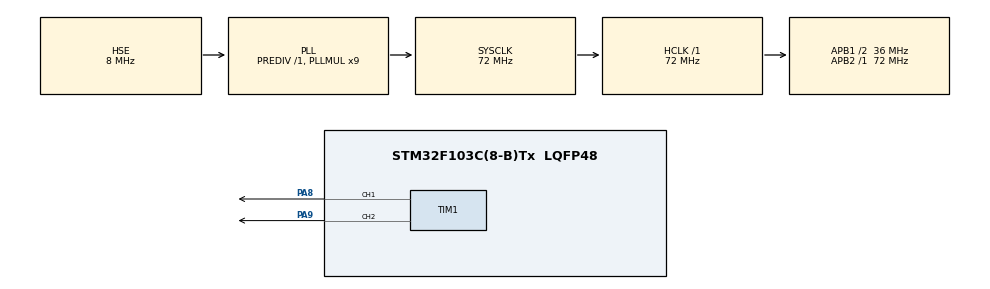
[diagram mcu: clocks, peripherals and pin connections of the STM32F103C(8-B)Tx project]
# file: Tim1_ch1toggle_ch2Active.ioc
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Mcu.Family=STM32F1
Mcu.Name=STM32F103C(8-B)Tx
Mcu.Package=LQFP48
NVIC.PriorityGroup=NVIC_PRIORITYGROUP_4
NVIC.TIM1_CC_IRQn=true\:0\:0\:false\:false\:true
PA13.Mode=Serial_Wire
PA13.Signal=SYS_JTMS-SWDIO
PA14.Mode=Serial_Wire
PA14.Signal=SYS_JTCK-SWCLK
PA8.GPIO_ModeDefaultPP=GPIO_MODE_AF_PP
PA8.GPIO_Speed=GPIO_SPEED_FREQ_HIGH
PA8.Signal=S_TIM1_CH1
PA9.GPIO_Speed=GPIO_SPEED_FREQ_HIGH
PA9.Signal=S_TIM1_CH2
PD0-OSC_IN.Mode=HSE-External-Oscillator
PD0-OSC_IN.Signal=RCC_OSC_IN
PD1-OSC_OUT.Mode=HSE-External-Oscillator
PD1-OSC_OUT.Signal=RCC_OSC_OUT
ProjectManager.HeapSize=0x200
ProjectManager.StackSize=0x400
ProjectManager.TargetToolchain=SW4STM32
RCC.AHBFreq_Value=72000000
RCC.APB1CLKDivider=RCC_HCLK_DIV2
RCC.APB1Freq_Value=36000000
RCC.APB1TimFreq_Value=72000000
RCC.APB2Freq_Value=72000000
RCC.APB2TimFreq_Value=72000000
RCC.HCLKFreq_Value=72000000
RCC.PLLMUL=RCC_PLL_MUL9
RCC.PLLSourceVirtual=RCC_PLLSOURCE_HSE
RCC.SYSCLKFreq_VALUE=72000000
RCC.SYSCLKSource=RCC_SYSCLKSOURCE_PLLCLK
RCC.USBFreq_Value=72000000
SH.S_TIM1_CH1.0=TIM1_CH1,Output Compare1 CH1
SH.S_TIM1_CH2.0=TIM1_CH2,Output Compare2 CH2
TIM1.Channel-Output\ Compare1\ CH1=TIM_CHANNEL_1
TIM1.Channel-Output\ Compare2\ CH2=TIM_CHANNEL_2
TIM1.OCMode_1=TIM_OCMODE_TOGGLE
TIM1.OCMode_2=TIM_OCMODE_TOGGLE
TIM1.TIM_MasterOutputTrigger=TIM_TRGO_OC1
VP_TIM1_VS_ClockSourceINT.Mode=Internal
board=Tim1_ch1toggle_ch2Active

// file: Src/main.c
/**
  ******************************************************************************
  * File Name          : main.c
  * Description        : Main program body
  ******************************************************************************
  ** This notice applies to any and all portions of this file
  * that are not between comment pairs USER CODE BEGIN and
  * USER CODE END. Other portions of this file, whether
  * inserted by the user or by software development tools
  * are owned by their respective copyright owners.
  *
  * COPYRIGHT(c) 2017 STMicroelectronics
  *
  * Redistribution and use in source and binary forms, with or without modification,
  * are permitted provided that the following conditions are met:
  *   1. Redistributions of source code must retain the above copyright notice,
  *      this list of conditions and the following disclaimer.
  *   2. Redistributions in binary form must reproduce the above copyright notice,
  *      this list of conditions and the following disclaimer in the documentation
  *      and/or other materials provided with the distribution.
  *   3. Neither the name of STMicroelectronics nor the names of its contributors
  *      may be used to endorse or promote products derived from this software
  *      without specific prior written permission.
  *
  * THIS SOFTWARE IS PROVIDED BY THE COPYRIGHT HOLDERS AND CONTRIBUTORS "AS IS"
  * AND ANY EXPRESS OR IMPLIED WARRANTIES, INCLUDING, BUT NOT LIMITED TO, THE
  * IMPLIED WARRANTIES OF MERCHANTABILITY AND FITNESS FOR A PARTICULAR PURPOSE ARE
  * DISCLAIMED. IN NO EVENT SHALL THE COPYRIGHT HOLDER OR CONTRIBUTORS BE LIABLE
  * FOR ANY DIRECT, INDIRECT, INCIDENTAL, SPECIAL, EXEMPLARY, OR CONSEQUENTIAL
  * DAMAGES (INCLUDING, BUT NOT LIMITED TO, PROCUREMENT OF SUBSTITUTE GOODS OR
  * SERVICES; LOSS OF USE, DATA, OR PROFITS; OR BUSINESS INTERRUPTION) HOWEVER
  * CAUSED AND ON ANY THEORY OF LIABILITY, WHETHER IN CONTRACT, STRICT LIABILITY,
  * OR TORT (INCLUDING NEGLIGENCE OR OTHERWISE) ARISING IN ANY WAY OUT OF THE USE
  * OF THIS SOFTWARE, EVEN IF ADVISED OF THE POSSIBILITY OF SUCH DAMAGE.
  *
  ******************************************************************************
  */
#include "main.h"
#include "stm32f1xx_hal.h"

TIM_HandleTypeDef htim1;

/* USER CODE BEGIN PV */
/* Private variables ---------------------------------------------------------*/

__IO uint32_t uhCCR1_Val = 16384;
__IO uint32_t uhCCR2_Val = 20480;
__IO uint32_t uhCCR3_Val = 10240;
__IO uint32_t uhCCR4_Val = 5120;
uint32_t uhCapture = 0;

/* Timer handler declaration */
TIM_HandleTypeDef TimHandle;

/* Timer Output Compare Configuration Structure declaration */
TIM_OC_InitTypeDef sConfig;

/* Counter Prescaler value */
uint32_t uwPrescalerValue = 0;

/* USER CODE END PV */

void SystemClock_Config(void);
static void MX_GPIO_Init(void);
static void MX_TIM1_Init(void);
void HAL_TIM_MspPostInit(TIM_HandleTypeDef *htim);

/* USER CODE BEGIN PFP */
/* Private function prototypes -----------------------------------------------*/
void configureTimerFrequencyOC(TIM_TypeDef* timx, uint32_t frequency,
		uint32_t channelx, uint8_t dutyCycle);
void HAL_TIM_OC_DelayElapsedCallback(TIM_HandleTypeDef *htim)
{
  /* TIM3_CH1 toggling with frequency = 256.35 Hz */
  if(htim->Channel == HAL_TIM_ACTIVE_CHANNEL_1)
  {
    uhCapture = HAL_TIM_ReadCapturedValue(htim, TIM_CHANNEL_1);
    /* Set the Capture Compare Register value */
    __HAL_TIM_SetCompare(&TimHandle, TIM_CHANNEL_1, (uhCapture + uhCCR1_Val));
  }

  /* TIM3_CH2 toggling with frequency = 256.35 Hz */
  if(htim->Channel == HAL_TIM_ACTIVE_CHANNEL_2)
  {
    uhCapture = HAL_TIM_ReadCapturedValue(htim, TIM_CHANNEL_2);
    /* Set the Capture Compare Register value */
    __HAL_TIM_SetCompare(&TimHandle, TIM_CHANNEL_2, (uhCapture + uhCCR2_Val));
  }

  /* TIM3_CH3 toggling with frequency = 256.35 Hz */
  if(htim->Channel == HAL_TIM_ACTIVE_CHANNEL_3)
  {
    uhCapture = HAL_TIM_ReadCapturedValue(htim, TIM_CHANNEL_3);
    /* Set the Capture Compare Register value */
    __HAL_TIM_SetCompare(&TimHandle, TIM_CHANNEL_3, (uhCapture + uhCCR3_Val));
  }

  /* TIM3_CH4 toggling with frequency = 256.35 Hz */
  if(htim->Channel == HAL_TIM_ACTIVE_CHANNEL_4)
  {
    uhCapture = HAL_TIM_ReadCapturedValue(htim, TIM_CHANNEL_4);
    /* Set the Capture Compare Register value */
    __HAL_TIM_SetCompare(&TimHandle, TIM_CHANNEL_4, (uhCapture + uhCCR4_Val));
  }
}
/* USER CODE END PFP */

/* USER CODE BEGIN 0 */
uint32_t uhTimerPeriod = 0;
/* USER CODE END 0 */

int main(void)
{

  /* MCU Configuration----------------------------------------------------------*/

  /* Reset of all peripherals, Initializes the Flash interface and the Systick. */
  HAL_Init();

  /* Configure the system clock */
  SystemClock_Config();

  /* Initialize all configured peripherals */
  MX_GPIO_Init();
  MX_TIM1_Init();

  /* USER CODE BEGIN 2 */
  uwPrescalerValue = (uint32_t)(((SystemCoreClock /2) / 21000000) - 1);
	TimHandle.Instance = TIM1;

	TimHandle.Init.Period = 65535;
	TimHandle.Init.Prescaler = 1;
	TimHandle.Init.ClockDivision = 0;
	TimHandle.Init.CounterMode = TIM_COUNTERMODE_UP;
	if (HAL_TIM_OC_Init(&TimHandle) != HAL_OK) {
		/* Initialization Error */
		Error_Handler();
	}

	//===============================================================

	sConfig.OCMode = TIM_OCMODE_TOGGLE;
	  sConfig.Pulse = uhCCR1_Val;
	  sConfig.OCPolarity = TIM_OCPOLARITY_LOW;
	  if(HAL_TIM_OC_ConfigChannel(&TimHandle, &sConfig, TIM_CHANNEL_1) != HAL_OK)
	  {
	    /* Configuration Error */
	    Error_Handler();
	  }

	  /* Output Compare Toggle Mode configuration: Channel2 */
	  sConfig.Pulse = uhCCR2_Val;
	  if(HAL_TIM_OC_ConfigChannel(&TimHandle, &sConfig, TIM_CHANNEL_2) != HAL_OK)
	  {
	    /* Configuration Error */
	    Error_Handler();
	  }

	  /* Output Compare Toggle Mode configuration: Channel3 */
	  sConfig.Pulse = uhCCR3_Val;
	  if(HAL_TIM_OC_ConfigChannel(&TimHandle, &sConfig, TIM_CHANNEL_3) != HAL_OK)
	  {
	    /* Configuration Error */
	    Error_Handler();
	  }

	  /* Output Compare Toggle Mode configuration: Channel4 */
	  sConfig.Pulse = uhCCR4_Val;
	  if(HAL_TIM_OC_ConfigChannel(&TimHandle, &sConfig, TIM_CHANNEL_4) != HAL_OK)
	  {
	    /* Configuration Error */
	    Error_Handler();
	  }

	    /*##-3- Start signals generation #######################################*/
	  /* Start channel 1 in Output compare mode */
	  if(HAL_TIM_OC_Start_IT(&TimHandle, TIM_CHANNEL_1) != HAL_OK)
	  {
	    /* Starting Error */
	    Error_Handler();
	  }
	  /* Start channel 2 in Output compare mode */
	  if(HAL_TIM_OC_Start_IT(&TimHandle, TIM_CHANNEL_2) != HAL_OK)
	  {
	    /* Starting Error */
	    Error_Handler();
	  }
	  /* Start channel 3 in Output compare mode */
	  if(HAL_TIM_OC_Start_IT(&TimHandle, TIM_CHANNEL_3) != HAL_OK)
	  {
	    /* Starting Error */
	    Error_Handler();
	  }
	  /* Start channel 4 in Output compare mode */
	  if(HAL_TIM_OC_Start_IT(&TimHandle, TIM_CHANNEL_4) != HAL_OK)
	  {
	    /* Starting Error */
	    Error_Handler();
	  }

  /* USER CODE END 2 */

  /* Infinite loop */
	while (1) {

	}

}

/** System Clock Configuration
*/
void SystemClock_Config(void)
{

  RCC_OscInitTypeDef RCC_OscInitStruct;
  RCC_ClkInitTypeDef RCC_ClkInitStruct;

    /**Initializes the CPU, AHB and APB busses clocks
    */
  RCC_OscInitStruct.OscillatorType = RCC_OSCILLATORTYPE_HSE;
  RCC_OscInitStruct.HSEState = RCC_HSE_ON;
  RCC_OscInitStruct.HSEPredivValue = RCC_HSE_PREDIV_DIV1;
  RCC_OscInitStruct.HSIState = RCC_HSI_ON;
  RCC_OscInitStruct.PLL.PLLState = RCC_PLL_ON;
  RCC_OscInitStruct.PLL.PLLSource = RCC_PLLSOURCE_HSE;
  RCC_OscInitStruct.PLL.PLLMUL = RCC_PLL_MUL9;
  if (HAL_RCC_OscConfig(&RCC_OscInitStruct) != HAL_OK)
  {
    _Error_Handler(__FILE__, __LINE__);
  }

    /**Initializes the CPU, AHB and APB busses clocks
    */
  RCC_ClkInitStruct.ClockType = RCC_CLOCKTYPE_HCLK|RCC_CLOCKTYPE_SYSCLK
                              |RCC_CLOCKTYPE_PCLK1|RCC_CLOCKTYPE_PCLK2;
  RCC_ClkInitStruct.SYSCLKSource = RCC_SYSCLKSOURCE_PLLCLK;
  RCC_ClkInitStruct.AHBCLKDivider = RCC_SYSCLK_DIV1;
  RCC_ClkInitStruct.APB1CLKDivider = RCC_HCLK_DIV2;
  RCC_ClkInitStruct.APB2CLKDivider = RCC_HCLK_DIV1;

  if (HAL_RCC_ClockConfig(&RCC_ClkInitStruct, FLASH_LATENCY_2) != HAL_OK)
  {
    _Error_Handler(__FILE__, __LINE__);
  }

    /**Configure the Systick interrupt time
    */
  HAL_SYSTICK_Config(HAL_RCC_GetHCLKFreq()/1000);

    /**Configure the Systick
    */
  HAL_SYSTICK_CLKSourceConfig(SYSTICK_CLKSOURCE_HCLK);

  /* SysTick_IRQn interrupt configuration */
  HAL_NVIC_SetPriority(SysTick_IRQn, 0, 0);
}

/* TIM1 init function */
static void MX_TIM1_Init(void)
{

  TIM_ClockConfigTypeDef sClockSourceConfig;
  TIM_MasterConfigTypeDef sMasterConfig;
  TIM_OC_InitTypeDef sConfigOC;
  TIM_BreakDeadTimeConfigTypeDef sBreakDeadTimeConfig;

  htim1.Instance = TIM1;
  htim1.Init.Prescaler = 0;
  htim1.Init.CounterMode = TIM_COUNTERMODE_UP;
  htim1.Init.Period = 0;
  htim1.Init.ClockDivision = TIM_CLOCKDIVISION_DIV1;
  htim1.Init.RepetitionCounter = 0;
  if (HAL_TIM_Base_Init(&htim1) != HAL_OK)
  {
    _Error_Handler(__FILE__, __LINE__);
  }

  sClockSourceConfig.ClockSource = TIM_CLOCKSOURCE_INTERNAL;
  if (HAL_TIM_ConfigClockSource(&htim1, &sClockSourceConfig) != HAL_OK)
  {
    _Error_Handler(__FILE__, __LINE__);
  }

  if (HAL_TIM_OC_Init(&htim1) != HAL_OK)
  {
    _Error_Handler(__FILE__, __LINE__);
  }

  sMasterConfig.MasterOutputTrigger = TIM_TRGO_OC1;
  sMasterConfig.MasterSlaveMode = TIM_MASTERSLAVEMODE_DISABLE;
  if (HAL_TIMEx_MasterConfigSynchronization(&htim1, &sMasterConfig) != HAL_OK)
  {
    _Error_Handler(__FILE__, __LINE__);
  }

  sConfigOC.OCMode = TIM_OCMODE_TOGGLE;
  sConfigOC.Pulse = 0;
  sConfigOC.OCPolarity = TIM_OCPOLARITY_HIGH;
  sConfigOC.OCNPolarity = TIM_OCNPOLARITY_HIGH;
  sConfigOC.OCFastMode = TIM_OCFAST_DISABLE;
  sConfigOC.OCIdleState = TIM_OCIDLESTATE_RESET;
  sConfigOC.OCNIdleState = TIM_OCNIDLESTATE_RESET;
  if (HAL_TIM_OC_ConfigChannel(&htim1, &sConfigOC, TIM_CHANNEL_1) != HAL_OK)
  {
    _Error_Handler(__FILE__, __LINE__);
  }

  if (HAL_TIM_OC_ConfigChannel(&htim1, &sConfigOC, TIM_CHANNEL_2) != HAL_OK)
  {
    _Error_Handler(__FILE__, __LINE__);
  }

  sBreakDeadTimeConfig.OffStateRunMode = TIM_OSSR_DISABLE;
  sBreakDeadTimeConfig.OffStateIDLEMode = TIM_OSSI_DISABLE;
  sBreakDeadTimeConfig.LockLevel = TIM_LOCKLEVEL_OFF;
  sBreakDeadTimeConfig.DeadTime = 0;
  sBreakDeadTimeConfig.BreakState = TIM_BREAK_DISABLE;
  sBreakDeadTimeConfig.BreakPolarity = TIM_BREAKPOLARITY_HIGH;
  sBreakDeadTimeConfig.AutomaticOutput = TIM_AUTOMATICOUTPUT_DISABLE;
  if (HAL_TIMEx_ConfigBreakDeadTime(&htim1, &sBreakDeadTimeConfig) != HAL_OK)
  {
    _Error_Handler(__FILE__, __LINE__);
  }

  HAL_TIM_MspPostInit(&htim1);

}

/** Configure pins as
        * Analog
        * Input
        * Output
        * EVENT_OUT
        * EXTI
*/
static void MX_GPIO_Init(void)
{

  /* GPIO Ports Clock Enable */
  __HAL_RCC_GPIOD_CLK_ENABLE();
  __HAL_RCC_GPIOA_CLK_ENABLE();

}

/* USER CODE BEGIN 4 */
/*	@brief	-	To configure Timer period (1/ frequency) with the prescalerValue and timerPeriod.
 * 				Also configure the chosen channelx with OCmode_PWM1
 * 	@param	-	timx 		:	timer chosen = TIM1, TIM2, ...
 * 				frequency	: 	in kHz, minimum a 1kHz.
 * 				channelx	:	channel chosen to generate PWM = TIM_CHANNEL_1, TIM_CHANNEL_2, ...
 * 				dutyCycle	:	The period of 'High' level before going 'Low' (in %)
 * 								e.g. : duty cycle = 10 :
 * 																   ______________
 * 															______|
 * 															10%		90%
 *
 *	@retVal	-	NON-value
 */
void configureTimerFrequencyOC(TIM_TypeDef* timx, uint32_t frequency,
		uint32_t channelx, uint8_t dutyCycle) //, uint32_t ocMode, uint32_t ocPolarity, uint32_t ocFastMode, uint32_t ocNPolarity, uint32_t ocNIdleState, uint32_t ocIdleState)//, uint32_t period)
{
	TIM_HandleTypeDef TimHandle;

	/* Timer Output Compare Configuration Structure declaration */
	TIM_OC_InitTypeDef sConfig;

	TimHandle.Instance = timx;
	uint16_t prescalerValue = (uint16_t) (SystemCoreClock / (frequency * 65536));
	uint16_t timerPeriod = (uint16_t) (SystemCoreClock
			/ (frequency * (prescalerValue + 1))) - 1;

	TimHandle.Init.Prescaler = prescalerValue;
	TimHandle.Init.Period = timerPeriod;
	TimHandle.Init.ClockDivision = 0;
	TimHandle.Init.CounterMode = TIM_COUNTERMODE_UP;
	TimHandle.Init.RepetitionCounter = 0;
	if (HAL_TIM_PWM_Init(&TimHandle) != HAL_OK) {
		/* Initialization Error */
		Error_Handler();
	}
	uint32_t pulse = (TimHandle.Init.Period - 1) * dutyCycle / 100;

	// sConfig.OCMode       = TIM_OCMODE_PWM1;
	// sConfig.OCPolarity   = TIM_OCPOLARITY_HIGH;
	// sConfig.OCFastMode   = TIM_OCFAST_DISABLE;
	// sConfig.OCNPolarity  = TIM_OCNPOLARITY_HIGH;
	// sConfig.OCNIdleState = TIM_OCNIDLESTATE_RESET;
	// sConfig.OCIdleState  = TIM_OCIDLESTATE_RESET;

	/* Set the pulse value for channel 1 */
	sConfig.Pulse = pulse;
	if (HAL_TIM_PWM_ConfigChannel(&TimHandle, &sConfig, channelx) != HAL_OK) {
		/* Configuration Error */
		Error_Handler();
	}

	if (HAL_TIM_PWM_Start(&TimHandle, channelx) != HAL_OK) {
		/* PWM Generation Error */
		Error_Handler();
	}

}
/* USER CODE END 4 */

void _Error_Handler(char * file, int line)
{
	while (1) {
	}
}

/************************ (C) COPYRIGHT STMicroelectronics *****END OF FILE****/
